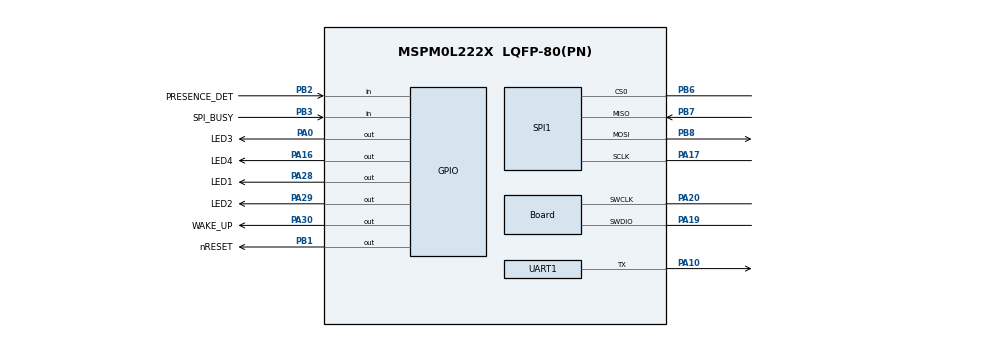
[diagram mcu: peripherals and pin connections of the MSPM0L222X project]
/**
 * @cliArgs --device "MSPM0L222X" --part "Default" --package "LQFP-80(PN)" --product "mspm0_sdk@2.10.00.04"
 * @versions {"tool":"1.27.0+4565"}
 */

/**
 * Import the modules used in this configuration.
 */
const CRCP    = scripting.addModule("/ti/driverlib/CRCP");
const GPIO    = scripting.addModule("/ti/driverlib/GPIO", {}, false);
const GPIO1   = GPIO.addInstance();
const GPIO2   = GPIO.addInstance();
const LCD     = scripting.addModule("/ti/driverlib/LCD");
const SPI     = scripting.addModule("/ti/driverlib/SPI", {}, false);
const SPI1    = SPI.addInstance();
const SYSCTL  = scripting.addModule("/ti/driverlib/SYSCTL");
const SYSTICK = scripting.addModule("/ti/driverlib/SYSTICK");
const UART    = scripting.addModule("/ti/driverlib/UART", {}, false);
const UART1   = UART.addInstance();

/**
 * Write custom configuration values to the imported modules.
 */
CRCP.bitReverse = "REVERSED";
CRCP.seed       = 0xFFFFFFFF;

const Board                       = scripting.addModule("/ti/driverlib/Board", {}, false);
Board.peripheral.$assign          = "DEBUGSS";
Board.peripheral.swclkPin.$assign = "PA20";
Board.peripheral.swdioPin.$assign = "PA19";

GPIO1.$name                             = "GPIO_LEDS";
GPIO1.associatedPins.create(4);
GPIO1.associatedPins[0].initialValue    = "SET";
GPIO1.associatedPins[0].$name           = "LED3";
GPIO1.associatedPins[0].pin.$assign     = "PA0";
GPIO1.associatedPins[1].$name           = "LED1";
GPIO1.associatedPins[1].subOutputPolicy = "CLEAR";
GPIO1.associatedPins[1].initialValue    = "SET";
GPIO1.associatedPins[1].pin.$assign     = "PA28";
GPIO1.associatedPins[2].$name           = "LED2";
GPIO1.associatedPins[2].subOutputPolicy = "CLEAR";
GPIO1.associatedPins[2].initialValue    = "SET";
GPIO1.associatedPins[2].pin.$assign     = "PA29";
GPIO1.associatedPins[3].$name           = "LED4";
GPIO1.associatedPins[3].pin.$assign     = "PA16";

GPIO2.$name                         = "CFG";
GPIO2.associatedPins.create(4);
GPIO2.associatedPins[0].$name       = "WAKE_UP";
GPIO2.associatedPins[0].pin.$assign = "PA30";
GPIO2.associatedPins[1].$name       = "SPI_BUSY";
GPIO2.associatedPins[1].direction   = "INPUT";
GPIO2.associatedPins[1].pin.$assign = "PB3";
GPIO2.associatedPins[2].$name       = "PRESENCE_DET";
GPIO2.associatedPins[2].direction   = "INPUT";
GPIO2.associatedPins[2].interruptEn = true;
GPIO2.associatedPins[2].polarity    = "RISE_FALL";
GPIO2.associatedPins[2].pin.$assign = "PB2";
GPIO2.associatedPins[3].$name       = "nRESET";
GPIO2.associatedPins[3].pin.$assign = "PB1";

LCD.freqDiv                                     = 4;
LCD.biasVSource                                 = "AVDD";
LCD.pumpFreq                                    = "1024HZ";
LCD.biasEnable                                  = true;
LCD.associatedCOM.create(4);
LCD.associatedCOM[0].$name                      = "LCD_COM_0";
LCD.associatedCOM[0].peripheral.LCDCom.$assign  = "PB24";
LCD.associatedCOM[1].$name                      = "LCD_COM_1";
LCD.associatedCOM[1].peripheral.LCDCom.$assign  = "PB25";
LCD.associatedCOM[2].$name                      = "LCD_COM_2";
LCD.associatedCOM[2].peripheral.LCDCom.$assign  = "PB26";
LCD.associatedCOM[3].$name                      = "LCD_COM_3";
LCD.associatedCOM[3].peripheral.LCDCom.$assign  = "PB27";
LCD.associatedSEG.create(24);
LCD.associatedSEG[0].$name                      = "LCD_SEGMENT_LINE_58";
LCD.associatedSEG[0].peripheral.LCDSeg.$assign  = "PC9";
LCD.associatedSEG[1].$name                      = "LCD_SEGMENT_LINE_57";
LCD.associatedSEG[1].peripheral.LCDSeg.$assign  = "PC8";
LCD.associatedSEG[2].$name                      = "LCD_SEGMENT_LINE_56";
LCD.associatedSEG[2].peripheral.LCDSeg.$assign  = "PC7";
LCD.associatedSEG[3].$name                      = "LCD_SEGMENT_LINE_55";
LCD.associatedSEG[3].peripheral.LCDSeg.$assign  = "PC6";
LCD.associatedSEG[4].$name                      = "LCD_SEGMENT_LINE_36";
LCD.associatedSEG[4].peripheral.LCDSeg.$assign  = "PB11";
LCD.associatedSEG[5].$name                      = "LCD_SEGMENT_LINE_37";
LCD.associatedSEG[5].peripheral.LCDSeg.$assign  = "PB12";
LCD.associatedSEG[6].$name                      = "LCD_SEGMENT_LINE_38";
LCD.associatedSEG[6].peripheral.LCDSeg.$assign  = "PB13";
LCD.associatedSEG[7].$name                      = "LCD_SEGMENT_LINE_18";
LCD.associatedSEG[7].peripheral.LCDSeg.$assign  = "PB17";
LCD.associatedSEG[8].$name                      = "LCD_SEGMENT_LINE_19";
LCD.associatedSEG[8].peripheral.LCDSeg.$assign  = "PB18";
LCD.associatedSEG[9].$name                      = "LCD_SEGMENT_LINE_20";
LCD.associatedSEG[9].peripheral.LCDSeg.$assign  = "PB19";
LCD.associatedSEG[10].$name                     = "LCD_SEGMENT_LINE_23";
LCD.associatedSEG[10].peripheral.LCDSeg.$assign = "PB20";
LCD.associatedSEG[11].$name                     = "LCD_SEGMENT_LINE_39";
LCD.associatedSEG[11].peripheral.LCDSeg.$assign = "PB21";
LCD.associatedSEG[12].$name                     = "LCD_SEGMENT_LINE_40";
LCD.associatedSEG[12].peripheral.LCDSeg.$assign = "PB22";
LCD.associatedSEG[13].$name                     = "LCD_SEGMENT_LINE_41";
LCD.associatedSEG[13].peripheral.LCDSeg.$assign = "PB23";
LCD.associatedSEG[14].$name                     = "LCD_SEGMENT_LINE_54";
LCD.associatedSEG[14].peripheral.LCDSeg.$assign = "PC5";
LCD.associatedSEG[15].$name                     = "LCD_SEGMENT_LINE_53";
LCD.associatedSEG[15].peripheral.LCDSeg.$assign = "PC4";
LCD.associatedSEG[16].$name                     = "LCD_SEGMENT_LINE_52";
LCD.associatedSEG[16].peripheral.LCDSeg.$assign = "PC3";
LCD.associatedSEG[17].$name                     = "LCD_SEGMENT_LINE_51";
LCD.associatedSEG[17].peripheral.LCDSeg.$assign = "PC2";
LCD.associatedSEG[18].$name                     = "LCD_SEGMENT_LINE_50";
LCD.associatedSEG[18].peripheral.LCDSeg.$assign = "PC1";
LCD.associatedSEG[19].$name                     = "LCD_SEGMENT_LINE_49";
LCD.associatedSEG[19].peripheral.LCDSeg.$assign = "PC0";
LCD.associatedSEG[20].$name                     = "LCD_SEGMENT_LINE_48";
LCD.associatedSEG[20].peripheral.LCDSeg.$assign = "PB31";
LCD.associatedSEG[21].$name                     = "LCD_SEGMENT_LINE_47";
LCD.associatedSEG[21].peripheral.LCDSeg.$assign = "PB30";
LCD.associatedSEG[22].$name                     = "LCD_SEGMENT_LINE_46";
LCD.associatedSEG[22].peripheral.LCDSeg.$assign = "PB29";
LCD.associatedSEG[23].$name                     = "LCD_SEGMENT_LINE_45";
LCD.associatedSEG[23].peripheral.LCDSeg.$assign = "PB28";

SPI1.$name                          = "SPI_0";
SPI1.targetBitRate                  = 1000000;
SPI1.dataSize                       = 16;
SPI1.peripheral.$assign             = "SPI1";
SPI1.peripheral.sclkPin.$assign     = "PA17";
SPI1.peripheral.mosiPin.$assign     = "PB8";
SPI1.peripheral.misoPin.$assign     = "PB7";
SPI1.peripheral.cs0Pin.$assign      = "PB6";
SPI1.sclkPinConfig.$name            = "ti_driverlib_gpio_GPIOPinGeneric0";
SPI1.sclkPinConfig.enableConfig     = true;
SPI1.sclkPinConfig.internalResistor = "PULL_DOWN";
SPI1.mosiPinConfig.$name            = "ti_driverlib_gpio_GPIOPinGeneric1";
SPI1.misoPinConfig.$name            = "ti_driverlib_gpio_GPIOPinGeneric2";
SPI1.cs0PinConfig.$name             = "ti_driverlib_gpio_GPIOPinGeneric5";


SYSTICK.periodEnable  = true;
SYSTICK.period        = 16777215;
SYSTICK.systickEnable = true;

UART1.$name                    = "UART_0";
UART1.direction                = "TX";
UART1.enableFIFO               = true;
UART1.txFifoThreshold          = "DL_UART_TX_FIFO_LEVEL_1_4_EMPTY";
UART1.txPinConfig.$name        = "ti_driverlib_gpio_GPIOPinGeneric4";
UART1.peripheral.$assign       = "UART0";
UART1.peripheral.txPin.$assign = "PA10";

const ProjectConfig              = scripting.addModule("/ti/project_config/ProjectConfig", {}, false);
ProjectConfig.migrationCondition = true;

/**
 * Pinmux solution for unlocked pins/peripherals. This ensures that minor changes to the automatic solver in a future
 * version of the tool will not impact the pinmux you originally saw.  These lines can be completely deleted in order to
 * re-solve from scratch.
 */
CRCP.peripheral.$suggestSolution                  = "CRCP0";
LCD.associatedCOM[0].peripheral.$suggestSolution  = "LCD";
LCD.associatedCOM[1].peripheral.$suggestSolution  = "LCD";
LCD.associatedCOM[2].peripheral.$suggestSolution  = "LCD";
LCD.associatedCOM[3].peripheral.$suggestSolution  = "LCD";
LCD.associatedSEG[0].peripheral.$suggestSolution  = "LCD";
LCD.associatedSEG[1].peripheral.$suggestSolution  = "LCD";
LCD.associatedSEG[2].peripheral.$suggestSolution  = "LCD";
LCD.associatedSEG[3].peripheral.$suggestSolution  = "LCD";
LCD.associatedSEG[4].peripheral.$suggestSolution  = "LCD";
LCD.associatedSEG[5].peripheral.$suggestSolution  = "LCD";
LCD.associatedSEG[6].peripheral.$suggestSolution  = "LCD";
LCD.associatedSEG[7].peripheral.$suggestSolution  = "LCD";
LCD.associatedSEG[8].peripheral.$suggestSolution  = "LCD";
LCD.associatedSEG[9].peripheral.$suggestSolution  = "LCD";
LCD.associatedSEG[10].peripheral.$suggestSolution = "LCD";
LCD.associatedSEG[11].peripheral.$suggestSolution = "LCD";
LCD.associatedSEG[12].peripheral.$suggestSolution = "LCD";
LCD.associatedSEG[13].peripheral.$suggestSolution = "LCD";
LCD.associatedSEG[14].peripheral.$suggestSolution = "LCD";
LCD.associatedSEG[15].peripheral.$suggestSolution = "LCD";
LCD.associatedSEG[16].peripheral.$suggestSolution = "LCD";
LCD.associatedSEG[17].peripheral.$suggestSolution = "LCD";
LCD.associatedSEG[18].peripheral.$suggestSolution = "LCD";
LCD.associatedSEG[19].peripheral.$suggestSolution = "LCD";
LCD.associatedSEG[20].peripheral.$suggestSolution = "LCD";
LCD.associatedSEG[21].peripheral.$suggestSolution = "LCD";
LCD.associatedSEG[22].peripheral.$suggestSolution = "LCD";
LCD.associatedSEG[23].peripheral.$suggestSolution = "LCD";
LCD.peripheral.$suggestSolution                   = "LCD";
SYSCTL.peripheral.$suggestSolution                = "SYSCTL";
